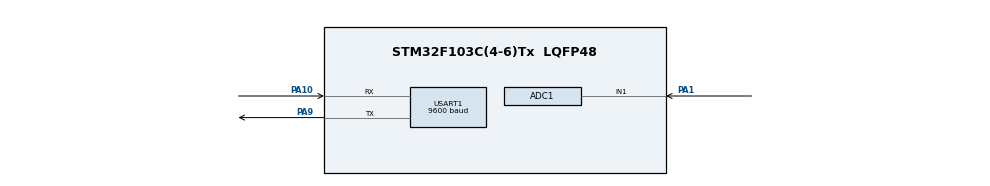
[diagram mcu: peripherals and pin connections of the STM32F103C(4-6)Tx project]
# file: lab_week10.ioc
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ADC1.Channel-0\#ChannelRegularConversion=ADC_CHANNEL_1
ADC1.NbrOfConversionFlag=1
ADC1.Rank-0\#ChannelRegularConversion=1
ADC1.SamplingTime-0\#ChannelRegularConversion=ADC_SAMPLETIME_1CYCLE_5
ADC1.master=1
Mcu.Family=STM32F1
Mcu.Name=STM32F103C(4-6)Tx
Mcu.Package=LQFP48
NVIC.PriorityGroup=NVIC_PRIORITYGROUP_4
PA1.Signal=ADCx_IN1
PA10.Mode=Asynchronous
PA10.Signal=USART1_RX
PA9.Mode=Asynchronous
PA9.Signal=USART1_TX
PD0-OSC_IN.Mode=HSE-External-Oscillator
PD0-OSC_IN.Signal=RCC_OSC_IN
PD1-OSC_OUT.Mode=HSE-External-Oscillator
PD1-OSC_OUT.Signal=RCC_OSC_OUT
ProjectManager.HeapSize=0x200
ProjectManager.StackSize=0x400
ProjectManager.TargetToolchain=MDK-ARM V5.32
RCC.APB1Freq_Value=8000000
RCC.APB2Freq_Value=8000000
SH.ADCx_IN1.0=ADC1_IN1,IN1
USART1.BaudRate=9600
USART1.VirtualMode=VM_ASYNC
VP_SYS_VS_ND.Mode=No_Debug
board=custom

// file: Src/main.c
/* USER CODE BEGIN Header */
/**
  ******************************************************************************
  * @file           : main.c
  * @brief          : Main program body
  ******************************************************************************
  * @attention
  *
  * Copyright (c) 2023 STMicroelectronics.
  * All rights reserved.
  *
  * This software is licensed under terms that can be found in the LICENSE file
  * in the root directory of this software component.
  * If no LICENSE file comes with this software, it is provided AS-IS.
  *
  ******************************************************************************
  */
/* USER CODE END Header */
#include "main.h"

/* USER CODE BEGIN Includes */
#include <stdio.h>
#include <string.h>

/* USER CODE END Includes */

ADC_HandleTypeDef hadc1;

UART_HandleTypeDef huart1;

void SystemClock_Config(void);
static void MX_GPIO_Init(void);
static void MX_ADC1_Init(void);
static void MX_USART1_UART_Init(void);

/* USER CODE BEGIN 0 */

uint32_t adcValue;

/* USER CODE END 0 */

int main(void)
{

  /* MCU Configuration--------------------------------------------------------*/

  /* Reset of all peripherals, Initializes the Flash interface and the Systick. */
  HAL_Init();

  /* Configure the system clock */
  SystemClock_Config();

  /* Initialize all configured peripherals */
  MX_GPIO_Init();
  MX_ADC1_Init();
  MX_USART1_UART_Init();
  /* USER CODE BEGIN 2 */
	HAL_ADCEx_Calibration_Start(&hadc1);
  float temperature;
  char buffer[50];
  float threshold = 32.0;

  /* USER CODE END 2 */

  /* Infinite loop */
  /* USER CODE BEGIN WHILE */
  while (1)
  {
		// ADC
		adcValue = 0;

		HAL_ADC_Start(&hadc1);

		if (HAL_ADC_PollForConversion(&hadc1, 100) == HAL_OK)
		{
			adcValue = HAL_ADC_GetValue(&hadc1);

			// float voltage = adcValue / 3.3 * 4096;
			// temperature = voltage / 0.01;
			float voltage = (float)adcValue * 3.3 / 4095.0;
			temperature = voltage * 100.0;

		// Convert temperature to string
		sprintf(buffer, "Temp: %.1f C\r\n", temperature);

		// Transmit temperature over USART1
    HAL_UART_Transmit(&huart1, (uint8_t*)buffer, strlen(buffer), HAL_MAX_DELAY);

    // Check if temperature exceeds threshold
    if (temperature > threshold) {
      sprintf(buffer, "FIRE ALARM!\r\n");
      HAL_UART_Transmit(&huart1, (uint8_t*)buffer, strlen(buffer), HAL_MAX_DELAY);
    }

    // Delay for some time
    HAL_Delay(1000);
		//HAL_UART_Receive(&huart1, (uint8_t *)data, sizeof(data), HAL_MAX_DELAY);
    /* USER CODE END WHILE */

	}
  }
}

void SystemClock_Config(void)
{
  RCC_OscInitTypeDef RCC_OscInitStruct = {0};
  RCC_ClkInitTypeDef RCC_ClkInitStruct = {0};
  RCC_PeriphCLKInitTypeDef PeriphClkInit = {0};

  /** Initializes the RCC Oscillators according to the specified parameters
  * in the RCC_OscInitTypeDef structure.
  */
  RCC_OscInitStruct.OscillatorType = RCC_OSCILLATORTYPE_HSI;
  RCC_OscInitStruct.HSIState = RCC_HSI_ON;
  RCC_OscInitStruct.HSICalibrationValue = RCC_HSICALIBRATION_DEFAULT;
  RCC_OscInitStruct.PLL.PLLState = RCC_PLL_NONE;
  if (HAL_RCC_OscConfig(&RCC_OscInitStruct) != HAL_OK)
  {
    Error_Handler();
  }

  /** Initializes the CPU, AHB and APB buses clocks
  */
  RCC_ClkInitStruct.ClockType = RCC_CLOCKTYPE_HCLK|RCC_CLOCKTYPE_SYSCLK
                              |RCC_CLOCKTYPE_PCLK1|RCC_CLOCKTYPE_PCLK2;
  RCC_ClkInitStruct.SYSCLKSource = RCC_SYSCLKSOURCE_HSI;
  RCC_ClkInitStruct.AHBCLKDivider = RCC_SYSCLK_DIV1;
  RCC_ClkInitStruct.APB1CLKDivider = RCC_HCLK_DIV1;
  RCC_ClkInitStruct.APB2CLKDivider = RCC_HCLK_DIV1;

  if (HAL_RCC_ClockConfig(&RCC_ClkInitStruct, FLASH_LATENCY_0) != HAL_OK)
  {
    Error_Handler();
  }
  PeriphClkInit.PeriphClockSelection = RCC_PERIPHCLK_ADC;
  PeriphClkInit.AdcClockSelection = RCC_ADCPCLK2_DIV2;
  if (HAL_RCCEx_PeriphCLKConfig(&PeriphClkInit) != HAL_OK)
  {
    Error_Handler();
  }
}

static void MX_ADC1_Init(void)
{

  ADC_ChannelConfTypeDef sConfig = {0};

  /** Common config
  */
  hadc1.Instance = ADC1;
  hadc1.Init.ScanConvMode = ADC_SCAN_DISABLE;
  hadc1.Init.ContinuousConvMode = DISABLE;
  hadc1.Init.DiscontinuousConvMode = DISABLE;
  hadc1.Init.ExternalTrigConv = ADC_SOFTWARE_START;
  hadc1.Init.DataAlign = ADC_DATAALIGN_RIGHT;
  hadc1.Init.NbrOfConversion = 1;
  if (HAL_ADC_Init(&hadc1) != HAL_OK)
  {
    Error_Handler();
  }

  /** Configure Regular Channel
  */
  sConfig.Channel = ADC_CHANNEL_1;
  sConfig.Rank = ADC_REGULAR_RANK_1;
  sConfig.SamplingTime = ADC_SAMPLETIME_1CYCLE_5;
  if (HAL_ADC_ConfigChannel(&hadc1, &sConfig) != HAL_OK)
  {
    Error_Handler();
  }

}

static void MX_USART1_UART_Init(void)
{

  huart1.Instance = USART1;
  huart1.Init.BaudRate = 9600;
  huart1.Init.WordLength = UART_WORDLENGTH_8B;
  huart1.Init.StopBits = UART_STOPBITS_1;
  huart1.Init.Parity = UART_PARITY_NONE;
  huart1.Init.Mode = UART_MODE_TX_RX;
  huart1.Init.HwFlowCtl = UART_HWCONTROL_NONE;
  huart1.Init.OverSampling = UART_OVERSAMPLING_16;
  if (HAL_UART_Init(&huart1) != HAL_OK)
  {
    Error_Handler();
  }

}

static void MX_GPIO_Init(void)
{

  /* GPIO Ports Clock Enable */
  __HAL_RCC_GPIOD_CLK_ENABLE();
  __HAL_RCC_GPIOA_CLK_ENABLE();

}

void Error_Handler(void)
{
  __disable_irq();
  while (1)
  {
  }
}
